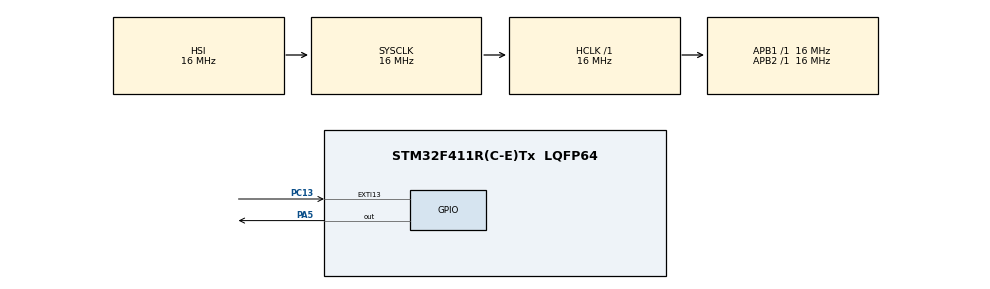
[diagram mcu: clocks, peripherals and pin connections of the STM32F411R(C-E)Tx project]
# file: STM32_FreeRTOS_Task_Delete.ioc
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Mcu.Family=STM32F4
Mcu.Name=STM32F411R(C-E)Tx
Mcu.Package=LQFP64
NVIC.EXTI15_10_IRQn=true\:0\:0\:false\:false\:true\:true\:true
NVIC.PriorityGroup=NVIC_PRIORITYGROUP_4
NVIC.TIM2_IRQn=true\:0\:0\:false\:false\:true\:false\:true
NVIC.TimeBase=TIM2_IRQn
NVIC.TimeBaseIP=TIM2
PA5.Signal=GPIO_Output
PC13-ANTI_TAMP.Signal=GPXTI13
ProjectManager.HeapSize=0x200
ProjectManager.StackSize=0x400
ProjectManager.TargetToolchain=STM32CubeIDE
RCC.AHBFreq_Value=16000000
RCC.APB1Freq_Value=16000000
RCC.APB2Freq_Value=16000000
RCC.CortexFreq_Value=16000000
RCC.HSE_VALUE=25000000
RCC.HSI_VALUE=16000000
RCC.LSE_VALUE=32768
RCC.SYSCLKFreq_VALUE=16000000
RCC.VCOOutputFreq_Value=192000000
VP_SYS_VS_tim2.Mode=TIM2
board=custom

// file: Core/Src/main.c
/* USER CODE BEGIN Header */
/**
  ******************************************************************************
  * @file           : main.c
  * @brief          : Main program body
  ******************************************************************************
  * @attention
  *
  * <h2><center>&copy; Copyright (c) 2021 STMicroelectronics.
  * All rights reserved.</center></h2>
  *
  * This software component is licensed by ST under BSD 3-Clause license,
  * the "License"; You may not use this file except in compliance with the
  * License. You may obtain a copy of the License at:
  *                        opensource.org/licenses/BSD-3-Clause
  *
  ******************************************************************************
  */
/* USER CODE END Header */

#include "main.h"

/* USER CODE BEGIN Includes */
#include "FreeRTOS.h"
#include "task.h"
#include "stdio.h"
#include "string.h"
/* USER CODE END Includes */

/* USER CODE BEGIN PM */
#define PRESSED 	1
#define NOT_PRESSED 0
/* USER CODE END PM */

void SystemClock_Config(void);
static void MX_GPIO_Init(void);
/* USER CODE BEGIN PFP */
void vTask1_handler(void);
void vTask2_handler(void);
void toggle_LED(void);
/* USER CODE END PFP */

/* USER CODE BEGIN 0 */
TaskHandle_t xTaskHandle_task1 = NULL;
TaskHandle_t xTaskHandle_task2 = NULL;
_Bool button_status = NOT_PRESSED;
/* USER CODE END 0 */

int main(void)
{

  /* MCU Configuration--------------------------------------------------------*/

  /* Reset of all peripherals, Initializes the Flash interface and the Systick. */
  HAL_Init();

  /* Configure the system clock */
  SystemClock_Config();

  /* Initialize all configured peripherals */
  MX_GPIO_Init();
  /* USER CODE BEGIN 2 */

  xTaskCreate((pdTASK_CODE) vTask1_handler, "Task1", 500, NULL, 1,
  			&xTaskHandle_task1);
  xTaskCreate((pdTASK_CODE) vTask2_handler, "Task2", 500, NULL, 2,
  			&xTaskHandle_task2);

  vTaskStartScheduler();
  /* USER CODE END 2 */

  /* Infinite loop */
  while (1)
  {

  }
}

void SystemClock_Config(void)
{
  RCC_OscInitTypeDef RCC_OscInitStruct = {0};
  RCC_ClkInitTypeDef RCC_ClkInitStruct = {0};

  /** Configure the main internal regulator output voltage
  */
  __HAL_RCC_PWR_CLK_ENABLE();
  __HAL_PWR_VOLTAGESCALING_CONFIG(PWR_REGULATOR_VOLTAGE_SCALE1);
  /** Initializes the CPU, AHB and APB busses clocks
  */
  RCC_OscInitStruct.OscillatorType = RCC_OSCILLATORTYPE_HSI;
  RCC_OscInitStruct.HSIState = RCC_HSI_ON;
  RCC_OscInitStruct.HSICalibrationValue = RCC_HSICALIBRATION_DEFAULT;
  RCC_OscInitStruct.PLL.PLLState = RCC_PLL_NONE;
  if (HAL_RCC_OscConfig(&RCC_OscInitStruct) != HAL_OK)
  {
    Error_Handler();
  }
  /** Initializes the CPU, AHB and APB busses clocks
  */
  RCC_ClkInitStruct.ClockType = RCC_CLOCKTYPE_HCLK|RCC_CLOCKTYPE_SYSCLK
                              |RCC_CLOCKTYPE_PCLK1|RCC_CLOCKTYPE_PCLK2;
  RCC_ClkInitStruct.SYSCLKSource = RCC_SYSCLKSOURCE_HSI;
  RCC_ClkInitStruct.AHBCLKDivider = RCC_SYSCLK_DIV1;
  RCC_ClkInitStruct.APB1CLKDivider = RCC_HCLK_DIV1;
  RCC_ClkInitStruct.APB2CLKDivider = RCC_HCLK_DIV1;

  if (HAL_RCC_ClockConfig(&RCC_ClkInitStruct, FLASH_LATENCY_0) != HAL_OK)
  {
    Error_Handler();
  }
}

static void MX_GPIO_Init(void)
{
  GPIO_InitTypeDef GPIO_InitStruct = {0};

  /* GPIO Ports Clock Enable */
  __HAL_RCC_GPIOC_CLK_ENABLE();
  __HAL_RCC_GPIOA_CLK_ENABLE();

  /*Configure GPIO pin Output Level */
  HAL_GPIO_WritePin(GPIOA, GPIO_PIN_5, GPIO_PIN_RESET);

  /*Configure GPIO pin : PC13 */
  GPIO_InitStruct.Pin = GPIO_PIN_13;
  GPIO_InitStruct.Mode = GPIO_MODE_IT_FALLING;
  GPIO_InitStruct.Pull = GPIO_NOPULL;
  HAL_GPIO_Init(GPIOC, &GPIO_InitStruct);

  /*Configure GPIO pin : PA5 */
  GPIO_InitStruct.Pin = GPIO_PIN_5;
  GPIO_InitStruct.Mode = GPIO_MODE_OUTPUT_PP;
  GPIO_InitStruct.Pull = GPIO_NOPULL;
  GPIO_InitStruct.Speed = GPIO_SPEED_FREQ_LOW;
  HAL_GPIO_Init(GPIOA, &GPIO_InitStruct);

  /* EXTI interrupt init*/
  HAL_NVIC_SetPriority(EXTI15_10_IRQn, 0, 0);
  HAL_NVIC_EnableIRQ(EXTI15_10_IRQn);

}

/* USER CODE BEGIN 4 */
void vTask1_handler(void) {
	while (1) {
			toggle_LED();
			vTaskDelay(2000); //2000ms period for LED toggling
		}
}

void vTask2_handler(void) {
	while (1) {
		if(button_status == NOT_PRESSED)
		{
			toggle_LED();
			vTaskDelay(500); //500ms period for LED toggling
		}
		else if(button_status == PRESSED)
		{
			vTaskDelete(NULL);
			button_status = NOT_PRESSED;
		}
	}
}

void toggle_LED(void) {
	if (!HAL_GPIO_ReadPin(GPIOA, GPIO_PIN_5))
		HAL_GPIO_WritePin(GPIOA, GPIO_PIN_5, GPIO_PIN_SET);
	else
		HAL_GPIO_WritePin(GPIOA, GPIO_PIN_5, GPIO_PIN_RESET);
}

void HAL_GPIO_EXTI_Callback(uint16_t GPIO_Pin)
{
	if(GPIO_Pin == GPIO_PIN_13)
	{
		button_status = PRESSED;
	}
}
/* USER CODE END 4 */

 /**
  * @brief  Period elapsed callback in non blocking mode
  * @note   This function is called  when TIM2 interrupt took place, inside
  * HAL_TIM_IRQHandler(). It makes a direct call to HAL_IncTick() to increment
  * a global variable "uwTick" used as application time base.
  * @param  htim : TIM handle
  * @retval None
  */
void HAL_TIM_PeriodElapsedCallback(TIM_HandleTypeDef *htim)
{
  if (htim->Instance == TIM2) {
    HAL_IncTick();
  }
}

void Error_Handler(void)
{
}

/************************ (C) COPYRIGHT STMicroelectronics *****END OF FILE****/
